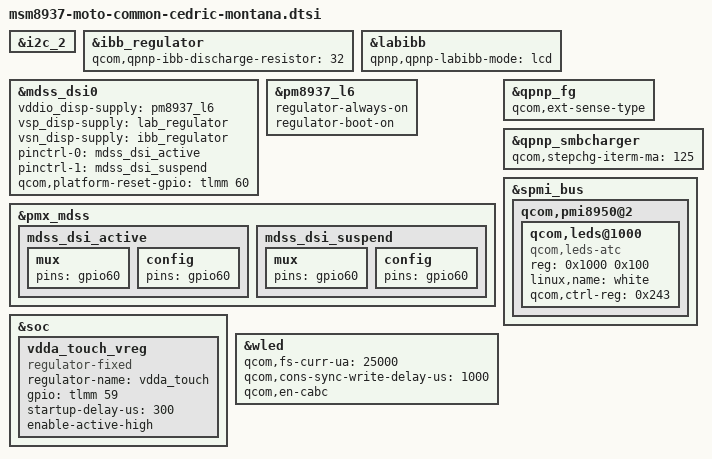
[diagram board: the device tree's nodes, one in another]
/* Copyright (c) 2020, The Linux Foundation. All rights reserved.
 *
 * This program is free software; you can redistribute it and/or modify
 * it under the terms of the GNU General Public License version 2 and
 * only version 2 as published by the Free Software Foundation.
 *
 * This program is distributed in the hope that it will be useful,
 * but WITHOUT ANY WARRANTY; without even the implied warranty of
 * MERCHANTABILITY or FITNESS FOR A PARTICULAR PURPOSE. See the
 * GNU General Public License for more details.
 *
 * Generated by wiktorek140 <wiktorek140@tlen.pl>
 */

#include "msm8937-moto-common-overlay.dtsi"

/*
 * Commonized more from cedric and montana
 * This file is only valid for mentioned devices.
 */

&i2c_2 {
	/delete-node/ adv7533@39;
	/delete-node/ pericom-type-c@1d;
};

&ibb_regulator {
	qcom,qpnp-ibb-discharge-resistor = <32>;
};

/* display boost and inverting boost regulators */
&labibb {
	status = "ok";
	qpnp,qpnp-labibb-mode = "lcd";
};

&mdss_dsi0 {
	vddio_disp-supply = <&pm8937_l6>;
	vsp_disp-supply = <&lab_regulator>;
	vsn_disp-supply = <&ibb_regulator>;

	pinctrl-names = "mdss_default", "mdss_sleep";
	pinctrl-0 = <&mdss_dsi_active>;
	pinctrl-1 = <&mdss_dsi_suspend>;

	qcom,platform-reset-gpio = <&tlmm 60 0>;
};

&pm8937_l6 {
	regulator-always-on;
	regulator-boot-on;
};

&pmx_mdss {
	mdss_dsi_active {
		mux {
			pins = "gpio60";
		};

		config {
			pins = "gpio60";
			/delete-property/ output-high;
		};
	};

	mdss_dsi_suspend {
		mux {
			pins = "gpio60";
		};

		config {
			pins = "gpio60";
		};
	};
};

&qpnp_fg {
	qcom,ext-sense-type; /* External Sense Resistor */
};

&qpnp_smbcharger {
	/delete-property/ qcom,dc-thermal-mitigation;
	qcom,stepchg-iterm-ma = <125>;
};

&soc {
	vdda_touch_vreg: vdda_touch_vreg {
		compatible = "regulator-fixed";
		regulator-name = "vdda_touch";
		gpio = <&tlmm 59 0>;
		startup-delay-us = <300>;
		enable-active-high;
	};
};

&spmi_bus {
	qcom,pmi8950@2 {
		/delete-node/ qcom,leds@a100;

		qcom,leds@1000 {
			status = "ok";
			reg = <0x1000 0x100>;
			compatible = "qcom,leds-atc";
			linux,name = "white";
			qcom,ctrl-reg = <0x243>;
		};
	};
};

&wled {
	qcom,fs-curr-ua = <25000>;
	qcom,cons-sync-write-delay-us = <1000>;
	qcom,en-cabc;
};
